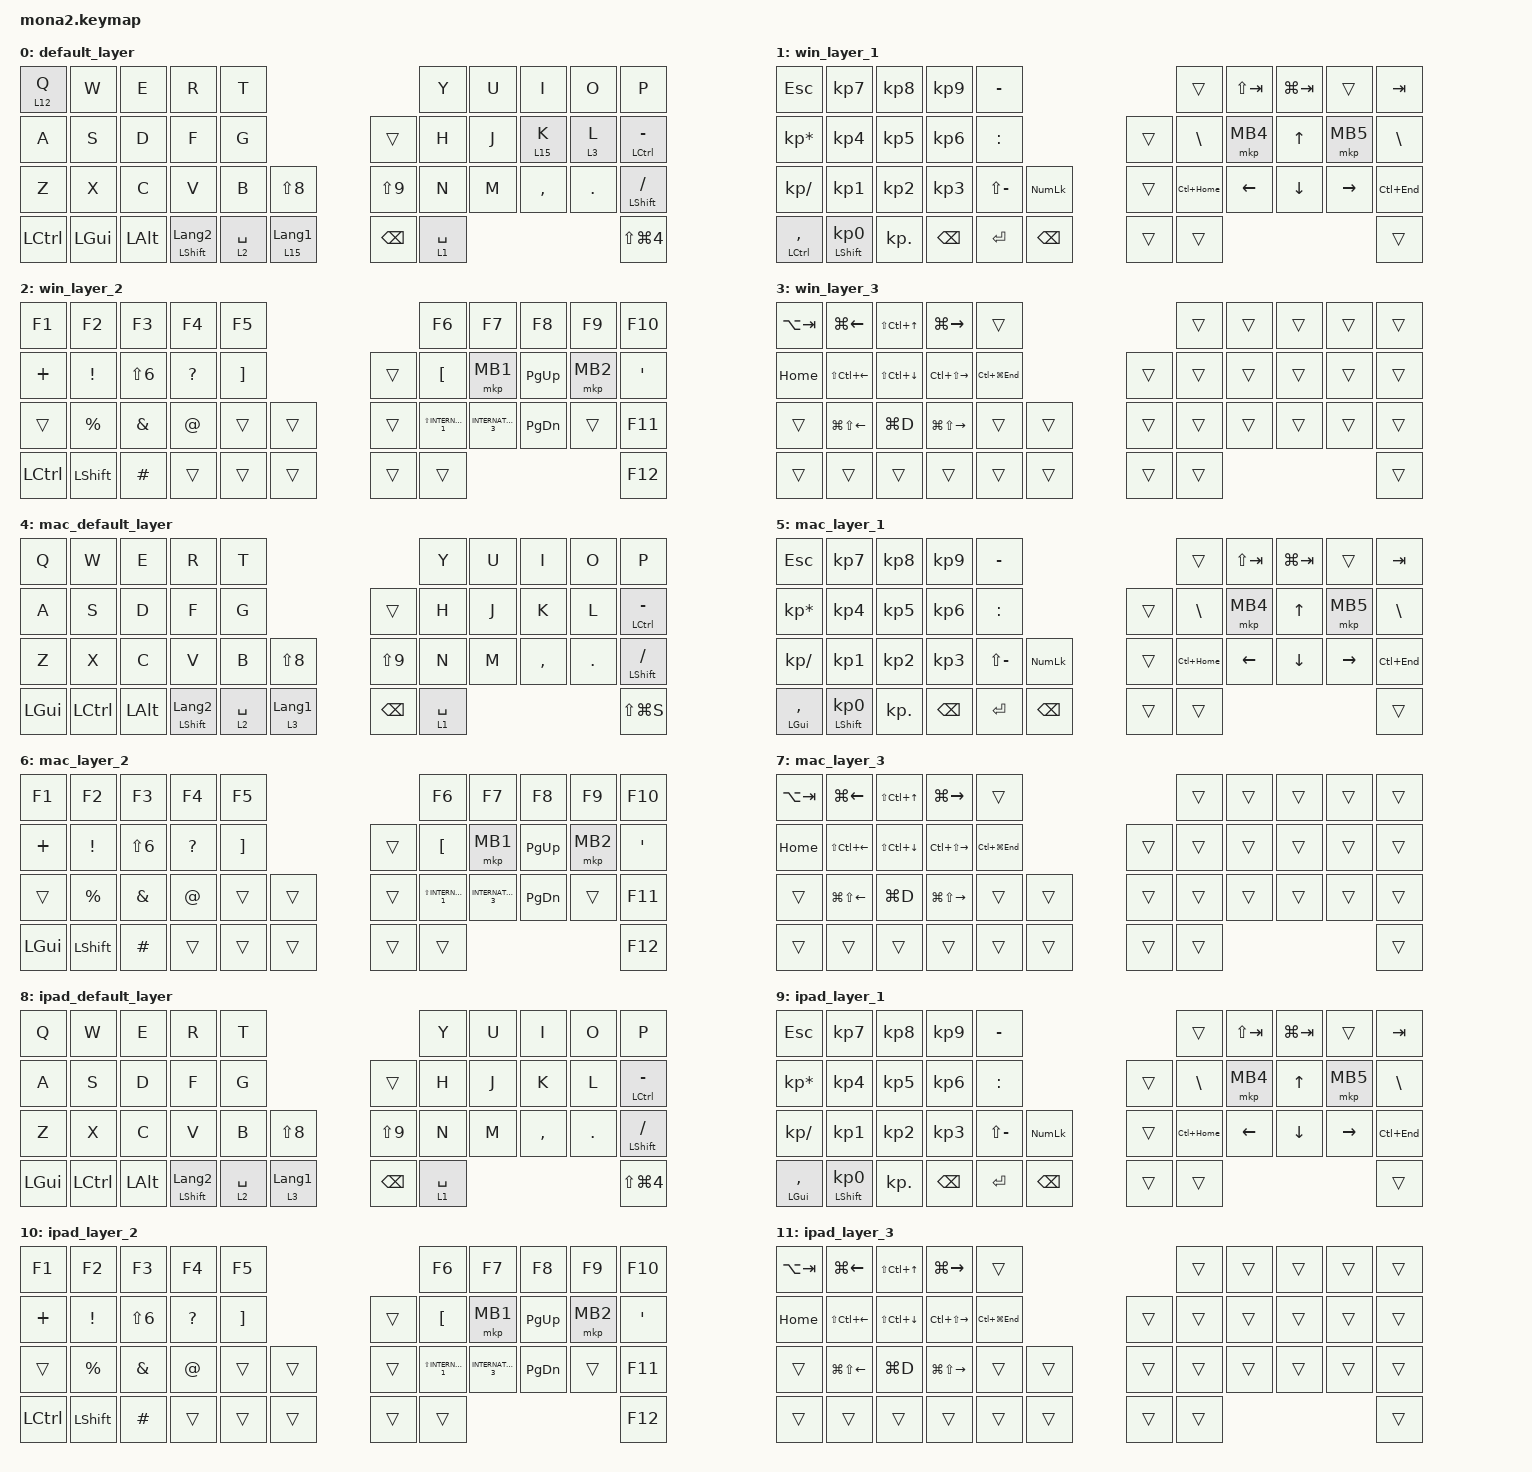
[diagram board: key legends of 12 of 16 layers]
#include <input/processors.dtsi>
#include <dt-bindings/zmk/input_transform.h>
#include <zephyr/dt-bindings/input/input-event-codes.h>

//#include "layout_shift.dtsi"

#include <layout_shift_kp_override.dtsi>
#include <behaviors.dtsi>
#include <dt-bindings/zmk/bt.h>
#include <dt-bindings/zmk/keys.h>
#include <dt-bindings/zmk/pointing.h>

#define ZMK_POINTING_DEFAULT_SCRL_VAL 100
#define MOUSE 13
#define SCROLL 15

&mt {
    flavor = "balanced";
    quick-tap-ms = <0>;
};

&lt {
    quick-tap-ms = <300>;
    flavor = "balanced";
};

/ {
    combos {
        compatible = "zmk,combos";

        alt+ctrl+del {
            bindings = <&kp LA(LC(DELETE))>;
            key-positions = <40 9>;
        };

        left_click {
            bindings = <&mkp MB1>;
            key-positions = <17 18>;
        };

        right_click {
            bindings = <&mkp MB2>;
            key-positions = <17 19>;
        };
    };

    macros {
        to_layer_0: to_layer_0 {
            compatible = "zmk,behavior-macro-one-param";
            #binding-cells = <1>;
            bindings = <&to 0 &macro_param_1to1 &kp MACRO_PLACEHOLDER>;
            label = "TO_LAYER_0";
        };

        macro0: macro1 {
            compatible = "zmk,behavior-macro";
            #binding-cells = <0>;
            bindings = <&kp LA(LC(V)) &kp V &kp ENTER>;
            label = "MACRO1";
        };

        macro1: macro2 {
            compatible = "zmk,behavior-macro";
            #binding-cells = <0>;
            bindings = <&kp LA(H) &kp M &kp C &kp ENTER>;
            label = "MACRO2";
        };

        macro2: macro3 {
            compatible = "zmk,behavior-macro";
            #binding-cells = <0>;
            bindings = <&kp LC(G) &kp LA(S) &kp K &kp ENTER>;
            label = "MACRO3";
        };

        macro3: macro0 {
            compatible = "zmk,behavior-macro";
            #binding-cells = <0>;
            bindings = <&kp LEFT_ALT &kp D &kp F &kp S>;
            label = "MACRO0";
        };

        mkp_exit_AML: mkp_exit_AML {
            compatible = "zmk,behavior-macro-one-param";
            #binding-cells = <1>;
            bindings =
                <&macro_press>,
                <&macro_param_1to1 &mkp MACRO_PLACEHOLDER>,
                <&macro_pause_for_release>,
                <&macro_release>,
                <&macro_param_1to1 &mkp MACRO_PLACEHOLDER>,
                <&macro_tap>,
                <&sl 13>;

            label = "MKP_EXIT_AML";
        };

        bt0: bt0 {
            compatible = "zmk,behavior-macro";
            #binding-cells = <0>;
            bindings =
                <&tog_off 4 &tog_off 8>,
                <&macro_wait_time 200>,
                <&bt BT_SEL 0>,
                <&macro_wait_time 500>,
                <&bt BT_DISC 1 &bt BT_DISC 2>;

            label = "BT0";
        };

        bt1: bt1 {
            compatible = "zmk,behavior-macro";
            #binding-cells = <0>;
            bindings =
                <&tog_off 0 &tog_off 4 &tog_off 8>,
                <&macro_wait_time 200>,
                <&bt BT_SEL 1>,
                <&macro_wait_time 500>,
                <&tog_on 4 &bt BT_DISC 0 &bt BT_DISC 2>;

            label = "BT1";
        };

        bt2: bt2 {
            compatible = "zmk,behavior-macro";
            #binding-cells = <0>;
            bindings =
                <&tog_off 0 &tog_off 4 &tog_off 8>,
                <&macro_wait_time 200>,
                <&bt BT_SEL 2>,
                <&macro_wait_time 500>,
                <&tog_on 8 &bt BT_DISC 0 &bt BT_DISC 1>;

            label = "BT2";
        };

        macro4_copy_lay15: macro_4 {
            compatible = "zmk,behavior-macro";
            #binding-cells = <0>;
            bindings = <&kp LS(LC(DOWN_ARROW)) &kp LS(LC(RIGHT_ARROW)) &kp LS(LC(RIGHT_ARROW)) &kp LC(C)>;
            label = "MACRO_4";
        };

        macro_5_copy_lay15: macro_5 {
            compatible = "zmk,behavior-macro";
            #binding-cells = <0>;
            bindings = <&kp LS(LC(RIGHT_ARROW)) &kp LS(LC(RIGHT_ARROW)) &kp LC(C)>;
            label = "MACRO_5";
        };

        macro_6_ketsugou_lay15: macro_6 {
            compatible = "zmk,behavior-macro";
            #binding-cells = <0>;
            bindings = <&kp LS(LC(DOWN_ARROW)) &kp LA(H) &kp M &kp C &kp ENTER>;
            label = "MACRO_6";
        };
    };

    behaviors {
        lt_to_layer_0: lt_to_layer_0 {
            compatible = "zmk,behavior-hold-tap";
            label = "LAYER_TAP_TO_0";
            bindings = <&mo>, <&to_layer_0>;

            #binding-cells = <2>;
            tapping-term-ms = <200>;
        };

        scroll_up_down: mouse_wheel_up_down {
            compatible = "zmk,behavior-sensor-rotate";
            #sensor-binding-cells = <0>;
            bindings = <&msc SCRL_DOWN>, <&msc SCRL_UP>;

            tap-ms = <20>;
        };

        scroll_right_left: mouse_wheel_right_left {
            compatible = "zmk,behavior-sensor-rotate";
            #sensor-binding-cells = <0>;
            bindings = <&msc SCRL_LEFT>, <&msc SCRL_RIGHT>;

            tap-ms = <20>;
        };

        tog_on: toggle_layer_on_only {
            compatible = "zmk,behavior-toggle-layer";
            #binding-cells = <1>;
            display-name = "Toggle Layer On";
            toggle-mode = "on";
        };

        tog_off: toggle_layer_off_only {
            compatible = "zmk,behavior-toggle-layer";
            #binding-cells = <1>;
            display-name = "Toggle Layer Off";
            toggle-mode = "off";
        };

        // Keep the original key_press behavior for ZMK core components

        original_key_press: original_key_press {
            compatible = "zmk,behavior-key-press";
            #binding-cells = <1>;
            label = "KEY_PRESS";
        };

        // Override the existing &kp behavior to use our custom implementation

        kp: key_press {
            compatible = "zmk,behavior-layout-shift-key-press";
            #binding-cells = <1>;
            label = "LAYOUT_SHIFT_KEY_PRESS";
        };

        // Layout shift toggle behaviors

        tog_ls: toggle_layout_shift {
            compatible = "zmk,behavior-layout-shift-toggle";
            #binding-cells = <0>;
            toggle-mode = "flip";
            label = "LAYOUT_SHIFT_TOGGLE";
        };

        tog_ls_on: toggle_layout_shift_on {
            compatible = "zmk,behavior-layout-shift-toggle";
            #binding-cells = <0>;
            toggle-mode = "on";
            label = "LAYOUT_SHIFT_TOGGLE_ON";
        };

        tog_ls_off: toggle_layout_shift_off {
            compatible = "zmk,behavior-layout-shift-toggle";
            #binding-cells = <0>;
            toggle-mode = "off";
            label = "LAYOUT_SHIFT_TOGGLE_OFF";
        };
    };

    keymap {
        compatible = "zmk,keymap";

        default_layer {
            bindings = <
&lt 12 Q   &kp W         &kp E         &kp R                      &kp T                                                       &kp Y        &kp U  &kp I      &kp O    &kp P
&kp A      &kp S         &kp D         &kp F                      &kp G                                        &trans         &kp H        &kp J  &lt 15 K   &lt 3 L  &mt LCTRL MINUS
&kp Z      &kp X         &kp C         &kp V                      &kp B        &kp LS(N8)                      &kp LS(N9)     &kp N        &kp M  &kp COMMA  &kp DOT  &mt LEFT_SHIFT SLASH
&kp LCTRL  &kp LEFT_GUI  &kp LEFT_ALT  &mt LEFT_SHIFT LANGUAGE_2  &lt 2 SPACE  &lt_to_layer_0 15 LANGUAGE_1    &kp BACKSPACE  &lt 1 SPACE                             &kp LS(LG(NUMBER_4))
            >;

            sensor-bindings = <&scroll_up_down>;
        };

        win_layer_1 {
            bindings = <
&kp ESCAPE       &kp KP_NUMBER_7             &kp KP_NUMBER_8  &kp KP_NUMBER_9  &kp MINUS                                &trans         &kp LS(TAB)  &kp LG(TAB)   &trans     &kp TAB
&kp KP_MULTIPLY  &kp KP_NUMBER_4             &kp KP_NUMBER_5  &kp KP_NUMBER_6  &kp COLON                        &trans  &kp BACKSLASH  &mkp MB4     &kp UP_ARROW  &mkp MB5   &kp BACKSLASH
&kp KP_SLASH     &kp KP_NUMBER_1             &kp KP_NUMBER_2  &kp KP_NUMBER_3  &kp LS(MINUS)  &kp KP_NUMLOCK    &trans  &kp LC(HOME)   &kp LEFT     &kp DOWN      &kp RIGHT  &kp LC(END)
&mt LCTRL COMMA  &mt LEFT_SHIFT KP_NUMBER_0  &kp KP_DOT       &kp BACKSPACE    &kp ENTER      &kp BACKSPACE     &trans  &trans                                               &trans
            >;

            sensor-bindings = <&scroll_right_left>;
        };

        win_layer_2 {
            bindings = <
&kp F1     &kp F2           &kp F3            &kp F4        &kp F5                               &kp F6                   &kp F7               &kp F8         &kp F9    &kp F10
&kp PLUS   &kp EXCLAMATION  &kp LS(NUMBER_6)  &kp QUESTION  &kp RIGHT_BRACKET            &trans  &kp LEFT_BRACKET         &mkp MB1             &kp PAGE_UP    &mkp MB2  &kp SINGLE_QUOTE
&trans     &kp PERCENT      &kp AMPERSAND     &kp AT_SIGN   &trans             &trans    &trans  &kp LS(INTERNATIONAL_1)  &kp INTERNATIONAL_3  &kp PAGE_DOWN  &trans    &kp F11
&kp LCTRL  &kp LEFT_SHIFT   &kp HASH          &trans        &trans             &trans    &trans  &trans                                                                 &kp F12
            >;

            sensor-bindings = <&scroll_up_down>;
        };

        win_layer_3 {
            bindings = <
&kp LA(TAB)  &kp LG(LEFT)            &kp LS(LC(UP_ARROW))    &kp LG(RIGHT)            &trans                             &trans  &trans  &trans  &trans  &trans
&kp HOME     &kp LS(LC(LEFT_ARROW))  &kp LS(LC(DOWN_ARROW))  &kp LC(LS(RIGHT_ARROW))  &kp LC(LG(END))            &trans  &trans  &trans  &trans  &trans  &trans
&trans       &kp LG(LS(LEFT_ARROW))  &kp LG(D)               &kp LG(LS(RIGHT_ARROW))  &trans           &trans    &trans  &trans  &trans  &trans  &trans  &trans
&trans       &trans                  &trans                  &trans                   &trans           &trans    &trans  &trans                          &trans
            >;

            sensor-bindings = <&inc_dec_kp C_VOL_DN C_VOL_UP>;
        };

        mac_default_layer {
            bindings = <
&kp Q         &kp W      &kp E         &kp R                      &kp T                                                      &kp Y        &kp U  &kp I      &kp O    &kp P
&kp A         &kp S      &kp D         &kp F                      &kp G                                       &trans         &kp H        &kp J  &kp K      &kp L    &mt LCTRL MINUS
&kp Z         &kp X      &kp C         &kp V                      &kp B        &kp LS(N8)                     &kp LS(N9)     &kp N        &kp M  &kp COMMA  &kp DOT  &mt LEFT_SHIFT SLASH
&kp LEFT_GUI  &kp LCTRL  &kp LEFT_ALT  &mt LEFT_SHIFT LANGUAGE_2  &lt 2 SPACE  &lt_to_layer_0 3 LANGUAGE_1    &kp BACKSPACE  &lt 1 SPACE                             &kp LS(LG(S))
            >;

            sensor-bindings = <&scroll_up_down>;
        };

        mac_layer_1 {
            bindings = <
&kp ESCAPE          &kp KP_NUMBER_7             &kp KP_NUMBER_8  &kp KP_NUMBER_9  &kp MINUS                                &trans         &kp LS(TAB)  &kp LG(TAB)   &trans     &kp TAB
&kp KP_MULTIPLY     &kp KP_NUMBER_4             &kp KP_NUMBER_5  &kp KP_NUMBER_6  &kp COLON                        &trans  &kp BACKSLASH  &mkp MB4     &kp UP_ARROW  &mkp MB5   &kp BACKSLASH
&kp KP_SLASH        &kp KP_NUMBER_1             &kp KP_NUMBER_2  &kp KP_NUMBER_3  &kp LS(MINUS)  &kp KP_NUMLOCK    &trans  &kp LC(HOME)   &kp LEFT     &kp DOWN      &kp RIGHT  &kp LC(END)
&mt LEFT_GUI COMMA  &mt LEFT_SHIFT KP_NUMBER_0  &kp KP_DOT       &kp BACKSPACE    &kp ENTER      &kp BACKSPACE     &trans  &trans                                               &trans
            >;

            sensor-bindings = <&scroll_right_left>;
        };

        mac_layer_2 {
            bindings = <
&kp F1        &kp F2           &kp F3            &kp F4        &kp F5                               &kp F6                   &kp F7               &kp F8         &kp F9    &kp F10
&kp PLUS      &kp EXCLAMATION  &kp LS(NUMBER_6)  &kp QUESTION  &kp RIGHT_BRACKET            &trans  &kp LEFT_BRACKET         &mkp MB1             &kp PAGE_UP    &mkp MB2  &kp SINGLE_QUOTE
&trans        &kp PERCENT      &kp AMPERSAND     &kp AT_SIGN   &trans             &trans    &trans  &kp LS(INTERNATIONAL_1)  &kp INTERNATIONAL_3  &kp PAGE_DOWN  &trans    &kp F11
&kp LEFT_GUI  &kp LEFT_SHIFT   &kp HASH          &trans        &trans             &trans    &trans  &trans                                                                 &kp F12
            >;

            sensor-bindings = <&scroll_up_down>;
        };

        mac_layer_3 {
            bindings = <
&kp LA(TAB)  &kp LG(LEFT)            &kp LS(LC(UP_ARROW))    &kp LG(RIGHT)            &trans                             &trans  &trans  &trans  &trans  &trans
&kp HOME     &kp LS(LC(LEFT_ARROW))  &kp LS(LC(DOWN_ARROW))  &kp LC(LS(RIGHT_ARROW))  &kp LC(LG(END))            &trans  &trans  &trans  &trans  &trans  &trans
&trans       &kp LG(LS(LEFT_ARROW))  &kp LG(D)               &kp LG(LS(RIGHT_ARROW))  &trans           &trans    &trans  &trans  &trans  &trans  &trans  &trans
&trans       &trans                  &trans                  &trans                   &trans           &trans    &trans  &trans                          &trans
            >;

            sensor-bindings = <&inc_dec_kp C_VOL_DN C_VOL_UP>;
        };

        ipad_default_layer {
            bindings = <
&kp Q         &kp W      &kp E         &kp R                      &kp T                                           &kp Y        &kp U  &kp I      &kp O    &kp P
&kp A         &kp S      &kp D         &kp F                      &kp G                            &trans         &kp H        &kp J  &kp K      &kp L    &mt LCTRL MINUS
&kp Z         &kp X      &kp C         &kp V                      &kp B        &kp LS(N8)          &kp LS(N9)     &kp N        &kp M  &kp COMMA  &kp DOT  &mt LEFT_SHIFT SLASH
&kp LEFT_GUI  &kp LCTRL  &kp LEFT_ALT  &mt LEFT_SHIFT LANGUAGE_2  &lt 2 SPACE  &lt 3 LANGUAGE_1    &kp BACKSPACE  &lt 1 SPACE                             &kp LS(LG(NUMBER_4))
            >;

            sensor-bindings = <&scroll_up_down>;
        };

        ipad_layer_1 {
            bindings = <
&kp ESCAPE          &kp KP_NUMBER_7             &kp KP_NUMBER_8  &kp KP_NUMBER_9  &kp MINUS                                &trans         &kp LS(TAB)  &kp LG(TAB)   &trans     &kp TAB
&kp KP_MULTIPLY     &kp KP_NUMBER_4             &kp KP_NUMBER_5  &kp KP_NUMBER_6  &kp COLON                        &trans  &kp BACKSLASH  &mkp MB4     &kp UP_ARROW  &mkp MB5   &kp BACKSLASH
&kp KP_SLASH        &kp KP_NUMBER_1             &kp KP_NUMBER_2  &kp KP_NUMBER_3  &kp LS(MINUS)  &kp KP_NUMLOCK    &trans  &kp LC(HOME)   &kp LEFT     &kp DOWN      &kp RIGHT  &kp LC(END)
&mt LEFT_GUI COMMA  &mt LEFT_SHIFT KP_NUMBER_0  &kp KP_DOT       &kp BACKSPACE    &kp ENTER      &kp BACKSPACE     &trans  &trans                                               &trans
            >;

            sensor-bindings = <&scroll_right_left>;
        };

        ipad_layer_2 {
            bindings = <
&kp F1     &kp F2           &kp F3            &kp F4        &kp F5                               &kp F6                   &kp F7               &kp F8         &kp F9    &kp F10
&kp PLUS   &kp EXCLAMATION  &kp LS(NUMBER_6)  &kp QUESTION  &kp RIGHT_BRACKET            &trans  &kp LEFT_BRACKET         &mkp MB1             &kp PAGE_UP    &mkp MB2  &kp SINGLE_QUOTE
&trans     &kp PERCENT      &kp AMPERSAND     &kp AT_SIGN   &trans             &trans    &trans  &kp LS(INTERNATIONAL_1)  &kp INTERNATIONAL_3  &kp PAGE_DOWN  &trans    &kp F11
&kp LCTRL  &kp LEFT_SHIFT   &kp HASH          &trans        &trans             &trans    &trans  &trans                                                                 &kp F12
            >;

            sensor-bindings = <&scroll_up_down>;
        };

        ipad_layer_3 {
            bindings = <
&kp LA(TAB)  &kp LG(LEFT)            &kp LS(LC(UP_ARROW))    &kp LG(RIGHT)            &trans                             &trans  &trans  &trans  &trans  &trans
&kp HOME     &kp LS(LC(LEFT_ARROW))  &kp LS(LC(DOWN_ARROW))  &kp LC(LS(RIGHT_ARROW))  &kp LC(LG(END))            &trans  &trans  &trans  &trans  &trans  &trans
&trans       &kp LG(LS(LEFT_ARROW))  &kp LG(D)               &kp LG(LS(RIGHT_ARROW))  &trans           &trans    &trans  &trans  &trans  &trans  &trans  &trans
&trans       &trans                  &trans                  &trans                   &trans           &trans    &trans  &trans                          &trans
            >;

            sensor-bindings = <&inc_dec_kp C_VOL_DN C_VOL_UP>;
        };

        bt_setting_layer {
            bindings = <
&trans  &trans  &trans  &tog_ls      &trans                              &bt0    &bt1          &bt2          &bt BT_SEL 3  &bt BT_SEL 4
&trans  &trans  &trans  &tog_ls_on   &trans                 &trans       &trans  &kp C_BRI_UP  &kp C_VOL_UP  &trans        &trans
&trans  &trans  &trans  &tog_ls_off  &trans  &bootloader    &bootloader  &trans  &kp C_BRI_DN  &kp C_VOL_DN  &trans        &bt BT_CLR
&trans  &trans  &trans  &trans       &trans  &trans         &trans       &trans                                            &bt BT_CLR_ALL
            >;

            sensor-bindings = <&scroll_up_down>;
        };

        MOUSE {
            bindings = <
&trans  &trans  &trans  &trans  &trans                    &trans  &trans              &trans  &trans              &trans
&trans  &trans  &trans  &trans  &trans            &trans  &trans  &mkp_exit_AML LCLK  &trans  &mkp_exit_AML RCLK  &trans
&trans  &trans  &trans  &trans  &trans  &trans    &trans  &trans  &trans              &trans  &trans              &trans
&trans  &trans  &trans  &trans  &trans  &trans    &trans  &trans                                                  &trans
            >;

            sensor-bindings = <&scroll_up_down>;
        };

        tenki_layer_14 {
            bindings = <
&trans  &trans  &trans  &trans  &trans                    &trans  &trans  &trans  &trans  &trans
&trans  &trans  &trans  &trans  &trans            &trans  &trans  &trans  &trans  &trans  &trans
&trans  &trans  &trans  &trans  &trans  &trans    &trans  &trans  &trans  &trans  &trans  &trans
&trans  &trans  &trans  &trans  &trans  &trans    &trans  &trans                          &trans
            >;

            sensor-bindings = <&scroll_up_down>;
        };

        SCROLL {
            bindings = <
&trans  &trans  &trans  &trans  &trans                    &trans  &trans  &trans  &trans  &trans
&trans  &trans  &trans  &trans  &trans            &trans  &trans  &trans  &trans  &trans  &trans
&trans  &trans  &trans  &trans  &trans  &trans    &trans  &trans  &trans  &trans  &trans  &trans
&trans  &trans  &trans  &trans  &trans  &trans    &trans  &trans                          &trans
            >;

            sensor-bindings = <&scroll_up_down>;
        };
    };
};
